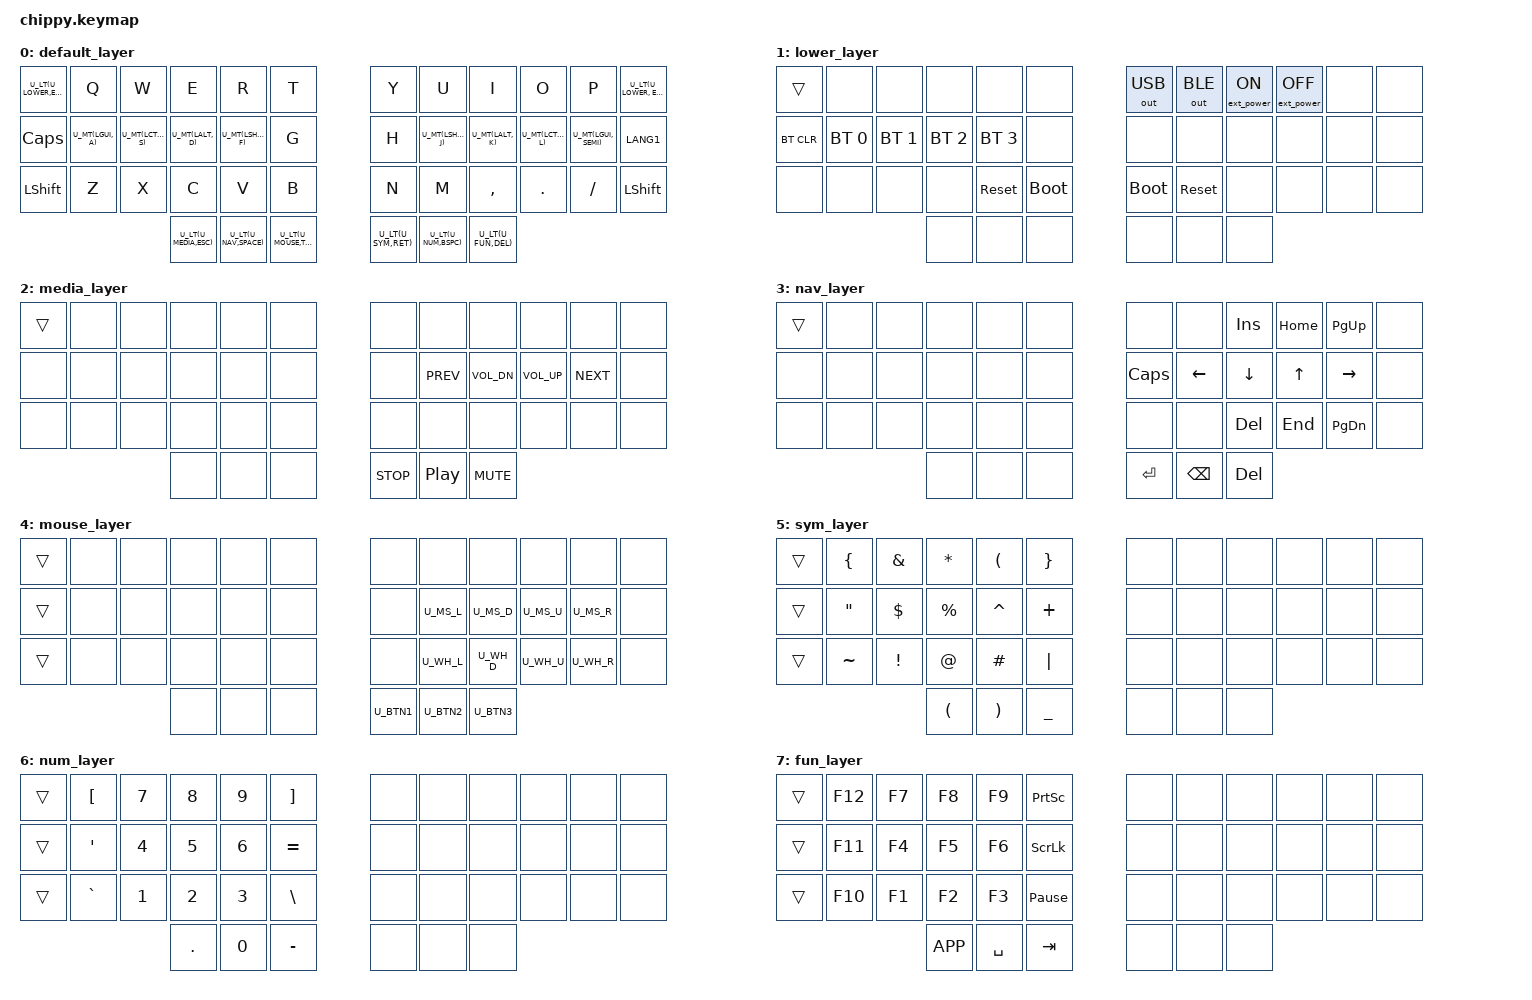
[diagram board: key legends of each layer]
/*
 * Copyright (c) 2020 The ZMK Contributors
 *
 * SPDX-License-Identifier: MIT
 */

#include <behaviors.dtsi>
#include <dt-bindings/zmk/keys.h>
#include <dt-bindings/zmk/bt.h>
#include <dt-bindings/zmk/outputs.h>
#include <dt-bindings/zmk/mouse.h>
#include <dt-bindings/zmk/ext_power.h>

#include "custom_config.h"
#include "chippy.h"

// Include Code
#include "miryoku_behaviors.dtsi"
#if defined (MIRYOKU_KLUDGE_MOUSEKEYSPR)
  #include "miryoku_kludge_mousekeyspr.dtsi"
#else
  #include "miryoku_mousekeys.dtsi"
#endif

#define U_DEFAULT 0
#define U_LOWER   1
#define U_MEDIA   2
#define U_NAV     3
#define U_MOUSE   4
#define U_SYM     5
#define U_NUM     6
#define U_FUN     7

&caps_word {
	continue-list = <UNDERSCORE MINUS BACKSPACE DELETE HOME END LEFT RIGHT>;
};

//&kscan0 {
//	debounce-period = <20>;
//	};

/ {
        keymap {
                compatible = "zmk,keymap";

                default_layer {
// -----------------------------------------------------------------------------------------
// |  Q  |  W  |  E  |  R  |  T  |   |  Y  |  U   |  I  |  O  |  P  | 
// |  A  |  S  |  D  |  F  |  G  |   |  H  |  J   |  K  |  L  |  ;  |
// |  Z  |  X  |  C  |  V  |  B  |   |  N  |  M   |  ,  |  .  |  /  | 
//             | GUI | LWR | ENT |   | SPC | RSE  | ALT |
                        bindings = <
U_LT(U_LOWER,ESC)  &kp Q              &kp W              &kp E              &kp R              &kp T              &kp Y              &kp U              &kp I              &kp O              &kp P              U_LT(U_LOWER, ESC)     
&kp CAPS           U_MT(LGUI, A)      U_MT(LCTRL, S)     U_MT(LALT, D)      U_MT(LSHFT, F)     &kp G              &kp H              U_MT(LSHFT, J)     U_MT(LALT, K)      U_MT(LCTRL, L)     U_MT(LGUI, SEMI)   &kp LANG1
&kp LSHFT          &kp Z              &kp X              &kp C              &kp V              &kp B              &kp N              &kp M              &kp COMMA          &kp DOT            &kp SLASH          &kp LSHFT
                                                         U_LT(U_MEDIA,ESC) U_LT(U_NAV,SPACE) U_LT(U_MOUSE,TAB) U_LT(U_SYM,RET)   U_LT(U_NUM,BSPC)  U_LT(U_FUN,DEL)
                        >;
                };
                lower_layer {
                        bindings = <
&trans             &none              &none              &none              &none              &none              &out OUT_USB       &out OUT_BLE       &ext_power EP_ON   &ext_power EP_OFF  &none              &none              
&bt BT_CLR         &bt BT_SEL 0       &bt BT_SEL 1       &bt BT_SEL 2       &bt BT_SEL 3       &none              &none              &none              &none              &none              &none              &none
&none              &none              &none              &none              &sys_reset         &bootloader        &bootloader        &sys_reset         &none              &none              &none              &none
                                                         &none              &none              &none              &none              &none              &none
                        >;
                };
                media_layer {
                        bindings = <
&trans             &none              &none              &none              &none              &none              &none              &none              &none              &none              &none              &none
&none              &none              &none              &none              &none              &none              &none              &kp C_PREV         &kp C_VOL_DN       &kp C_VOL_UP       &kp C_NEXT         &none
&none              &none              &none              &none              &none              &none              &none              &none              &none              &none              &none              &none
                                                         &none              &none              &none              &kp C_STOP         &kp C_PP           &kp C_MUTE         
                        >;
                };
                nav_layer {
                        bindings = <
&trans             &none              &none              &none              &none              &none              &none              &none              &kp INSERT         &kp HOME           &kp PG_UP          &none                          
&none              &none              &none              &none              &none              &none              &kp CAPS           &kp LEFT           &kp DOWN           &kp UP             &kp RIGHT          &none              
&none              &none              &none              &none              &none              &none              &none              &none              &kp DEL            &kp END            &kp PG_DN          &none                
                                                         &none              &none              &none              &kp RET            &kp BSPC           &kp DEL                               
                        >;
                };
                mouse_layer {
                        bindings = <
&trans             &none              &none              &none              &none              &none              &none              &none              &none              &none              &none              &none    
&trans             &none              &none              &none              &none              &none              &none              U_MS_L             U_MS_D             U_MS_U             U_MS_R             &none
&trans             &none              &none              &none              &none              &none              &none              U_WH_L             U_WH_D             U_WH_U             U_WH_R             &none
                                                         &none              &none              &none              U_BTN1             U_BTN2             U_BTN3             
                        >;
                };
                sym_layer {
                        bindings = <
&trans             &kp LBRC           &kp AMPS           &kp ASTRK          &kp LPAR           &kp RBRC           &none               &none              &none              &none              &none              &none
&trans             &kp DQT            &kp DLLR           &kp PRCNT          &kp CARET          &kp PLUS           &none               &none              &none              &none              &none              &none  
&trans             &kp TILDE          &kp EXCL           &kp AT             &kp HASH           &kp PIPE           &none               &none              &none              &none              &none              &none
                                                         &kp LPAR           &kp RPAR           &kp UNDER          &none               &none              &none                              

                        >;
                };
                num_layer {
                        bindings = <
&trans             &kp LBKT           &kp N7             &kp N8             &kp N9             &kp RBKT           &none               &none              &none              &none              &none              &none
&trans             &kp SQT            &kp N4             &kp N5             &kp N6             &kp EQUAL          &none               &none              &none              &none              &none              &none
&trans             &kp GRAVE          &kp N1             &kp N2             &kp N3             &kp BSLH           &none               &none              &none              &none              &none              &none
                                                         &kp DOT            &kp N0             &kp MINUS          &none               &none              &none

                        >;
                };
                fun_layer {
                        bindings = <
&trans             &kp F12            &kp F7             &kp F8             &kp F9             &kp PSCRN          &none               &none              &none              &none              &none              &none              
&trans             &kp F11            &kp F4             &kp F5             &kp F6             &kp SLCK           &none               &none              &none              &none              &none              &none                  
&trans             &kp F10            &kp F1             &kp F2             &kp F3             &kp PAUSE_BREAK    &none               &none              &none              &none              &none              &none  
                                                         &kp K_APP          &kp SPACE          &kp TAB            &none               &none              &none                              
                        >;
                };
        };
};

//&none                  &none              &none            &none             &none           &none             &none             &none             &none             &none             &none             &none
//&none                  &none              &none            &none             &none           &none             &none             &none             &none             &none             &none             &none
//&none                  &none              &none            &none             &none           &none             &none             &none             &none             &none             &none             &none
//                                                           &none             &none           &none             &none             &none             &none
                        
